# STM32U5xx register map
File version: 1.7
Registers are 32-bit, read-write, reset 0x0 unless marked. A register's access mark holds for its fields unless they carry their own. Offsets are from the block's base; [hi:lo] are bit positions; {n}, {i} and the like mark numbered series.

## DCMI — Digital camera interface
Base 0x4202C000
Same registers: SEC_DCMI 0x5202C000
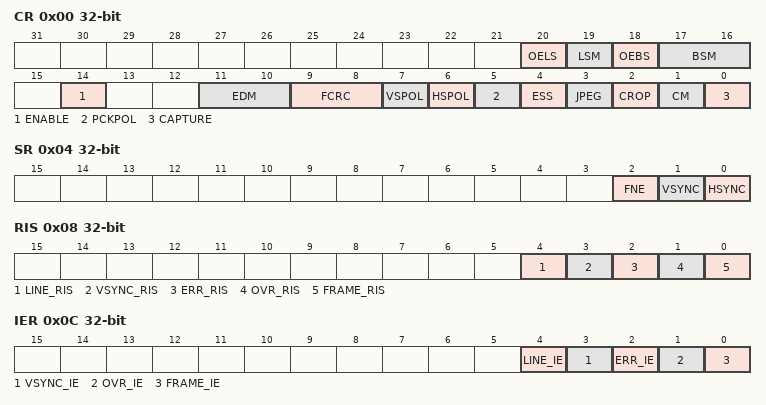
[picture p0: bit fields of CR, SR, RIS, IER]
0x00 CR — control register
  [20] OELS — Odd/Even Line Select (Line Select Start)
  [19] LSM — Line Select mode
  [18] OEBS — Odd/Even Byte Select (Byte Select Start)
  [17:16] BSM — Byte Select mode
  [14] ENABLE — DCMI enable
  [11:10] EDM — Extended data mode
  [9:8] FCRC — Frame capture rate control
  [7] VSPOL — Vertical synchronization polarity
  [6] HSPOL — Horizontal synchronization polarity
  [5] PCKPOL — Pixel clock polarity
  [4] ESS — Embedded synchronization select
  [3] JPEG — JPEG format
  [2] CROP — Crop feature
  [1] CM — Capture mode
  [0] CAPTURE — Capture enable
0x04 SR ro — status register
  [2] FNE — FIFO not empty
  [1] VSYNC — Vertical synchronization
  [0] HSYNC — Horizontal synchronization
0x08 RIS ro — raw interrupt status register
  [4] LINE_RIS — Line raw interrupt status
  [3] VSYNC_RIS — DCMI_VSYNC raw interrupt status
  [2] ERR_RIS — Synchronization error raw interrupt status
  [1] OVR_RIS — Overrun raw interrupt status
  [0] FRAME_RIS — Capture complete raw interrupt status
0x0C IER — interrupt enable register
  [4] LINE_IE — Line interrupt enable
  [3] VSYNC_IE — DCMI_VSYNC interrupt enable
  [2] ERR_IE — Synchronization error interrupt enable
  [1] OVR_IE — Overrun interrupt enable
  [0] FRAME_IE — Capture complete interrupt enable
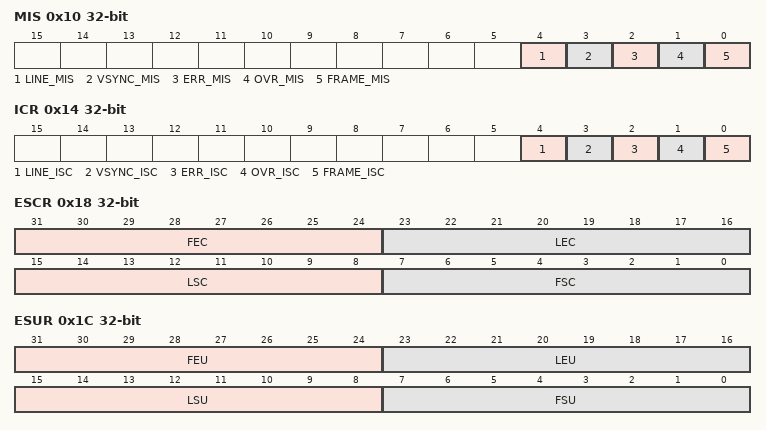
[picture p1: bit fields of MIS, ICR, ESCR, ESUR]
0x10 MIS ro — masked interrupt status register
  [4] LINE_MIS — Line masked interrupt status
  [3] VSYNC_MIS — VSYNC masked interrupt status
  [2] ERR_MIS — Synchronization error masked interrupt status
  [1] OVR_MIS — Overrun masked interrupt status
  [0] FRAME_MIS — Capture complete masked interrupt status
0x14 ICR wo — interrupt clear register
  [4] LINE_ISC — line interrupt status clear
  [3] VSYNC_ISC — Vertical Synchronization interrupt status clear
  [2] ERR_ISC — Synchronization error interrupt status clear
  [1] OVR_ISC — Overrun interrupt status clear
  [0] FRAME_ISC — Capture complete interrupt status clear
0x18 ESCR — background offset register
  [31:24] FEC — Frame end delimiter code
  [23:16] LEC — Line end delimiter code
  [15:8] LSC — Line start delimiter code
  [7:0] FSC — Frame start delimiter code
0x1C ESUR — embedded synchronization unmask register
  [31:24] FEU — Frame end delimiter unmask
  [23:16] LEU — Line end delimiter unmask
  [15:8] LSU — Line start delimiter unmask
  [7:0] FSU — Frame start delimiter unmask
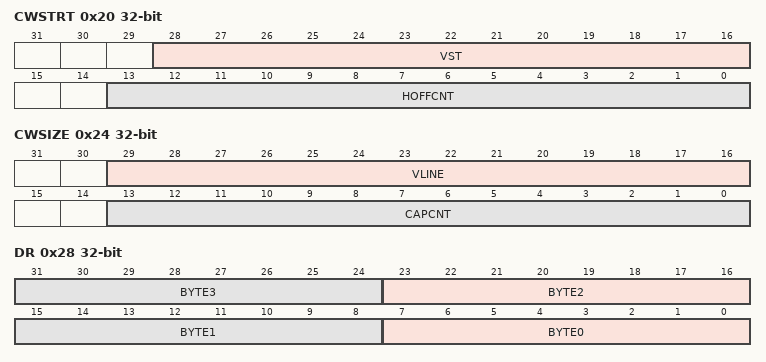
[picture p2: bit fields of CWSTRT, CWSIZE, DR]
0x20 CWSTRT — crop window start
  [28:16] VST — Vertical start line count
  [13:0] HOFFCNT — Horizontal offset count
0x24 CWSIZE — crop window size
  [29:16] VLINE — Vertical line count
  [13:0] CAPCNT — Capture count
0x28 DR ro — data register
  [8n+7:8n] BYTE{n} (n=0..3) — Data byte {n}

## NVIC — Nested Vectored Interrupt Controller
Base 0xE000E100
{0x0+4i} ISER{i} (i=0..2) — Interrupt Set-Enable Register
  [31:0] SETENA
0x0C ISER3 — Interrupt Set-Enable Register
{0x80+4i} ICER{i} (i=0..2) — Interrupt Clear-Enable Register
  [31:0] CLRENA
0x8C ICER3 — Interrupt Clear-Enable Register
{0x100+4i} ISPR{i} (i=0..2) — Interrupt Set-Pending Register
  [31:0] SETPEND
0x10C ISPR3 — Interrupt Set-Pending Register
{0x180+4i} ICPR{i} (i=0..2) — Interrupt Clear-Pending Register
  [31:0] CLRPEND
0x18C ICPR3 — Interrupt Clear-Pending Register
{0x200+4i} IABR{i} ro (i=0..2) — Interrupt Active Bit Register
  [31:0] ACTIVE
0x20C IABR3 — Interrupt Active Bit Register
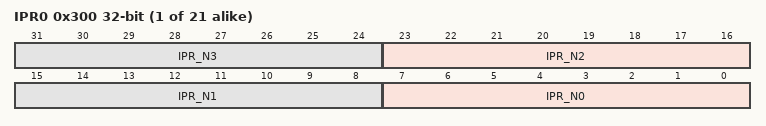
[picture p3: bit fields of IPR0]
{0x300+4i} IPR{i} (i=0..20) — Interrupt Priority Register
  [8n+7:8n] IPR_N{n} (n=0..3)
{0x300+4i} IPR{i} (i=21..29)

## NVIC_STIR — Nested vectored interrupt controller
Base 0xE000EF00
0x00 STIR — Software trigger interrupt register
  [8:0] INTID — Software generated interrupt ID
